AUTOSAR XML (schema 4-2-2)
package /ComponentTypes
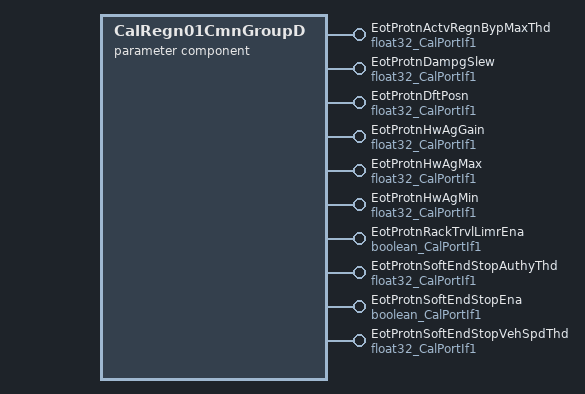
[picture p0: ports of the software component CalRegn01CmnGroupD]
  parameter sw component type CalRegn01CmnGroupD
    10 x provide port:
      EotProtnActvRegnBypMaxThd: parameter-provide-com-spec{init-value=0.5, parameter=Val}, provided-interface=float32_CalPortIf1
      EotProtnDampgSlew: parameter-provide-com-spec{init-value=400, parameter=Val}, provided-interface=float32_CalPortIf1
      EotProtnDftPosn: parameter-provide-com-spec{init-value=100, parameter=Val}, provided-interface=float32_CalPortIf1
      EotProtnHwAgGain: parameter-provide-com-spec{init-value=0.15, parameter=Val}, provided-interface=float32_CalPortIf1
      EotProtnHwAgMax: parameter-provide-com-spec{init-value=600, parameter=Val}, provided-interface=float32_CalPortIf1
      EotProtnHwAgMin: parameter-provide-com-spec{init-value=550, parameter=Val}, provided-interface=float32_CalPortIf1
      EotProtnRackTrvlLimrEna: parameter-provide-com-spec{init-value=0, parameter=Logl}, provided-interface=boolean_CalPortIf1
      EotProtnSoftEndStopAuthyThd: parameter-provide-com-spec{init-value=0.9, parameter=Val}, provided-interface=float32_CalPortIf1
      EotProtnSoftEndStopEna: parameter-provide-com-spec{init-value=0, parameter=Logl}, provided-interface=boolean_CalPortIf1
      EotProtnSoftEndStopVehSpdThd: parameter-provide-com-spec{init-value=30, parameter=Val}, provided-interface=float32_CalPortIf1
